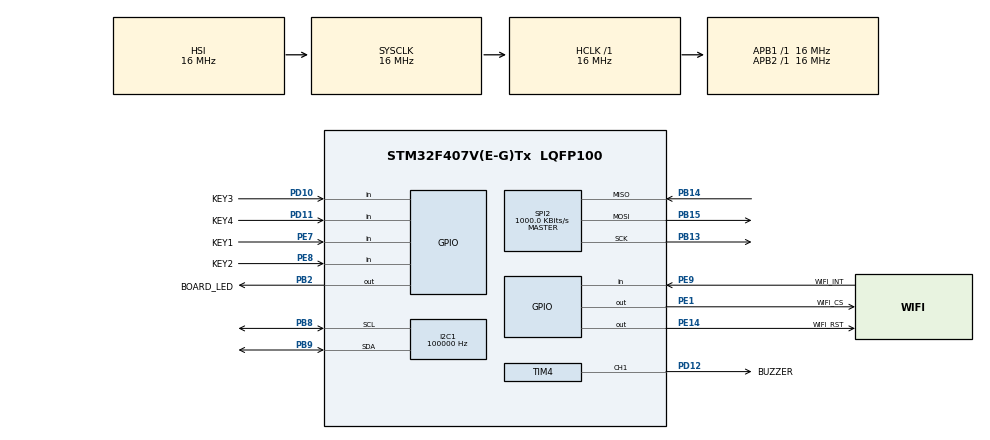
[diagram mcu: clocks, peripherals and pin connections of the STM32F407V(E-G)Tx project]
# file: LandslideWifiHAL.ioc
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Mcu.Family=STM32F4
Mcu.Name=STM32F407V(E-G)Tx
Mcu.Package=LQFP100
NVIC.PriorityGroup=NVIC_PRIORITYGROUP_4
PA13.Mode=Serial_Wire
PA13.Signal=SYS_JTMS-SWDIO
PA14.Mode=Serial_Wire
PA14.Signal=SYS_JTCK-SWCLK
PB8.Mode=I2C
PB8.Signal=I2C1_SCL
PB9.Mode=I2C
PB9.Signal=I2C1_SDA
PB13.Mode=Full_Duplex_Master
PB13.Signal=SPI2_SCK
PB14.Mode=Full_Duplex_Master
PB14.Signal=SPI2_MISO
PB15.Mode=Full_Duplex_Master
PB15.Signal=SPI2_MOSI
PB2.GPIO_Label=BOARD_LED
PB2.Signal=GPIO_Output
PD12.GPIO_Label=BUZZER
PD12.Mode=PWM Generation1 CH1
PD12.Signal=TIM4_CH1
PD10.GPIO_Label=KEY3
PD10.Signal=GPIO_Input
PD11.GPIO_Label=KEY4
PD11.Signal=GPIO_Input
PE1.GPIO_Label=WIFI_CS
PE1.PinState=GPIO_PIN_SET
PE1.Signal=GPIO_Output
PE7.GPIO_Label=KEY1
PE7.Signal=GPIO_Input
PE8.GPIO_Label=KEY2
PE8.Signal=GPIO_Input
PE14.GPIO_Label=WIFI_RST
PE14.PinState=GPIO_PIN_SET
PE14.Signal=GPIO_Output
PE9.GPIO_Label=WIFI_INT
PE9.Signal=GPIO_Input
ProjectManager.HeapSize=0x200
ProjectManager.StackSize=0x400
ProjectManager.TargetToolchain=MDK-ARM V5.32
RCC.AHBFreq_Value=16000000
RCC.APB1Freq_Value=16000000
RCC.APB2Freq_Value=16000000
RCC.CortexFreq_Value=16000000
RCC.HSE_VALUE=25000000
RCC.HSI_VALUE=16000000
RCC.LSE_VALUE=32768
RCC.SYSCLKFreq_VALUE=16000000
RCC.VCOOutputFreq_Value=192000000
SPI2.BaudRatePrescaler=SPI_BAUDRATEPRESCALER_16
SPI2.CalculateBaudRate=1000.0 KBits/s
SPI2.Direction=SPI_DIRECTION_2LINES
SPI2.Mode=SPI_MODE_MASTER
SPI2.VirtualType=VM_MASTER
I2C1.ClockSpeed=100000
I2C1.DutyCycle=I2C_DUTYCYCLE_2
I2C1.Mode=I2C
I2C1.VirtualType=VM_MASTER
TIM4.AutoReloadPreload=TIM_AUTORELOAD_PRELOAD_DISABLE
TIM4.Channel-PWM\ Generation1=TIM_CHANNEL_1
TIM4.Period=1249
TIM4.Prescaler=15
SYS.Debug=Serial Wire
VP_TIM4_VS_ClockSourceINT.Mode=Internal
board=custom

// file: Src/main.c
/* USER CODE BEGIN Header */
/**
  ******************************************************************************
  * @file           : main.c
  * @brief          : Main program body
  ******************************************************************************
  * @attention
  *
  * Copyright (c) 2026 STMicroelectronics.
  * All rights reserved.
  *
  * This software is licensed under terms that can be found in the LICENSE file
  * in the root directory of this software component.
  * If no LICENSE file comes with this software, it is provided AS-IS.
  *
  ******************************************************************************
  */
/* USER CODE END Header */
#include "main.h"

/* USER CODE BEGIN Includes */
#include "app_all.h"

/* USER CODE END Includes */

SPI_HandleTypeDef hspi2;
TIM_HandleTypeDef htim4;
I2C_HandleTypeDef hi2c1;

void SystemClock_Config(void);
static void MX_GPIO_Init(void);
static void MX_SPI2_Init(void);
static void MX_TIM4_Init(void);
static void MX_I2C1_Init(void);

int main(void)
{

  /* MCU Configuration--------------------------------------------------------*/

  /* Reset of all peripherals, Initializes the Flash interface and the Systick. */
  HAL_Init();

  /* Configure the system clock */
  SystemClock_Config();

  /* Initialize all configured peripherals */
  MX_GPIO_Init();
  MX_SPI2_Init();
  MX_TIM4_Init();
  MX_I2C1_Init();
  /* USER CODE BEGIN 2 */
  OLED_UI_Init(&hi2c1);
  wifi_test_app_run(&hspi2);

  /* USER CODE END 2 */

  /* Infinite loop */
  while (1)
  {

  }
}

static void MX_I2C1_Init(void)
{
  hi2c1.Instance = I2C1;
  hi2c1.Init.ClockSpeed = 100000;
  hi2c1.Init.DutyCycle = I2C_DUTYCYCLE_2;
  hi2c1.Init.OwnAddress1 = 0;
  hi2c1.Init.AddressingMode = I2C_ADDRESSINGMODE_7BIT;
  hi2c1.Init.DualAddressMode = I2C_DUALADDRESS_DISABLE;
  hi2c1.Init.OwnAddress2 = 0;
  hi2c1.Init.GeneralCallMode = I2C_GENERALCALL_DISABLE;
  hi2c1.Init.NoStretchMode = I2C_NOSTRETCH_DISABLE;
  if (HAL_I2C_Init(&hi2c1) != HAL_OK) Error_Handler();
}

void SystemClock_Config(void)
{
  RCC_OscInitTypeDef RCC_OscInitStruct = {0};
  RCC_ClkInitTypeDef RCC_ClkInitStruct = {0};

  /** Configure the main internal regulator output voltage
  */
  __HAL_RCC_PWR_CLK_ENABLE();
  __HAL_PWR_VOLTAGESCALING_CONFIG(PWR_REGULATOR_VOLTAGE_SCALE1);

  /** Initializes the RCC Oscillators according to the specified parameters
  * in the RCC_OscInitTypeDef structure.
  */
  RCC_OscInitStruct.OscillatorType = RCC_OSCILLATORTYPE_HSI;
  RCC_OscInitStruct.HSIState = RCC_HSI_ON;
  RCC_OscInitStruct.HSICalibrationValue = RCC_HSICALIBRATION_DEFAULT;
  RCC_OscInitStruct.PLL.PLLState = RCC_PLL_NONE;
  if (HAL_RCC_OscConfig(&RCC_OscInitStruct) != HAL_OK)
  {
    Error_Handler();
  }

  /** Initializes the CPU, AHB and APB buses clocks
  */
  RCC_ClkInitStruct.ClockType = RCC_CLOCKTYPE_HCLK|RCC_CLOCKTYPE_SYSCLK
                              |RCC_CLOCKTYPE_PCLK1|RCC_CLOCKTYPE_PCLK2;
  RCC_ClkInitStruct.SYSCLKSource = RCC_SYSCLKSOURCE_HSI;
  RCC_ClkInitStruct.AHBCLKDivider = RCC_SYSCLK_DIV1;
  RCC_ClkInitStruct.APB1CLKDivider = RCC_HCLK_DIV1;
  RCC_ClkInitStruct.APB2CLKDivider = RCC_HCLK_DIV1;

  if (HAL_RCC_ClockConfig(&RCC_ClkInitStruct, FLASH_LATENCY_0) != HAL_OK)
  {
    Error_Handler();
  }
}

static void MX_SPI2_Init(void)
{

  /* SPI2 parameter configuration*/
  hspi2.Instance = SPI2;
  hspi2.Init.Mode = SPI_MODE_MASTER;
  hspi2.Init.Direction = SPI_DIRECTION_2LINES;
  hspi2.Init.DataSize = SPI_DATASIZE_8BIT;
  hspi2.Init.CLKPolarity = SPI_POLARITY_LOW;
  hspi2.Init.CLKPhase = SPI_PHASE_1EDGE;
  hspi2.Init.NSS = SPI_NSS_SOFT;
  hspi2.Init.BaudRatePrescaler = SPI_BAUDRATEPRESCALER_16;
  hspi2.Init.FirstBit = SPI_FIRSTBIT_MSB;
  hspi2.Init.TIMode = SPI_TIMODE_DISABLE;
  hspi2.Init.CRCCalculation = SPI_CRCCALCULATION_DISABLE;
  hspi2.Init.CRCPolynomial = 10;
  if (HAL_SPI_Init(&hspi2) != HAL_OK)
  {
    Error_Handler();
  }

}

static void MX_TIM4_Init(void)
{
  GPIO_InitTypeDef GPIO_InitStruct = {0};
  TIM_OC_InitTypeDef sConfigOC = {0};

  __HAL_RCC_TIM4_CLK_ENABLE();
  __HAL_RCC_GPIOD_CLK_ENABLE();

  htim4.Instance = TIM4;
  htim4.Init.Prescaler = 15;
  htim4.Init.CounterMode = TIM_COUNTERMODE_UP;
  htim4.Init.Period = 1249;
  htim4.Init.ClockDivision = TIM_CLOCKDIVISION_DIV1;
  htim4.Init.AutoReloadPreload = TIM_AUTORELOAD_PRELOAD_DISABLE;
  if (HAL_TIM_PWM_Init(&htim4) != HAL_OK) Error_Handler();

  sConfigOC.OCMode = TIM_OCMODE_PWM1;
  sConfigOC.Pulse = 0;
  sConfigOC.OCPolarity = TIM_OCPOLARITY_HIGH;
  sConfigOC.OCFastMode = TIM_OCFAST_DISABLE;
  if (HAL_TIM_PWM_ConfigChannel(&htim4, &sConfigOC, TIM_CHANNEL_1) != HAL_OK)
    Error_Handler();

  GPIO_InitStruct.Pin = BUZZER_Pin;
  GPIO_InitStruct.Mode = GPIO_MODE_AF_PP;
  GPIO_InitStruct.Pull = GPIO_NOPULL;
  GPIO_InitStruct.Speed = GPIO_SPEED_FREQ_LOW;
  GPIO_InitStruct.Alternate = GPIO_AF2_TIM4;
  HAL_GPIO_Init(BUZZER_GPIO_Port, &GPIO_InitStruct);

  if (HAL_TIM_PWM_Start(&htim4, TIM_CHANNEL_1) != HAL_OK) Error_Handler();
}

static void MX_GPIO_Init(void)
{
  GPIO_InitTypeDef GPIO_InitStruct = {0};

  /* GPIO Ports Clock Enable */
  __HAL_RCC_GPIOB_CLK_ENABLE();
  __HAL_RCC_GPIOE_CLK_ENABLE();
  __HAL_RCC_GPIOD_CLK_ENABLE();
  __HAL_RCC_GPIOA_CLK_ENABLE();

  /*Configure GPIO pin Output Level */
  HAL_GPIO_WritePin(BOARD_LED_GPIO_Port, BOARD_LED_Pin, GPIO_PIN_RESET);

  /*Configure GPIO pin Output Level */
  HAL_GPIO_WritePin(GPIOE, WIFI_RST_Pin|WIFI_CS_Pin, GPIO_PIN_SET);

  /*Configure GPIO pin : BOARD_LED_Pin */
  GPIO_InitStruct.Pin = BOARD_LED_Pin;
  GPIO_InitStruct.Mode = GPIO_MODE_OUTPUT_PP;
  GPIO_InitStruct.Pull = GPIO_NOPULL;
  GPIO_InitStruct.Speed = GPIO_SPEED_FREQ_LOW;
  HAL_GPIO_Init(BOARD_LED_GPIO_Port, &GPIO_InitStruct);

  /*Configure GPIO pin : WIFI_INT_Pin */
  GPIO_InitStruct.Pin = WIFI_INT_Pin;
  GPIO_InitStruct.Mode = GPIO_MODE_INPUT;
  GPIO_InitStruct.Pull = GPIO_NOPULL;
  HAL_GPIO_Init(WIFI_INT_GPIO_Port, &GPIO_InitStruct);

  /*Configure GPIO pins : WIFI_RST_Pin WIFI_CS_Pin */
  GPIO_InitStruct.Pin = WIFI_RST_Pin|WIFI_CS_Pin;
  GPIO_InitStruct.Mode = GPIO_MODE_OUTPUT_PP;
  GPIO_InitStruct.Pull = GPIO_NOPULL;
  GPIO_InitStruct.Speed = GPIO_SPEED_FREQ_LOW;
  HAL_GPIO_Init(GPIOE, &GPIO_InitStruct);

  /* USER CODE BEGIN MX_GPIO_Init_2 */

  GPIO_InitStruct.Pin = KEY1_Pin|KEY2_Pin;
  GPIO_InitStruct.Mode = GPIO_MODE_INPUT;
  GPIO_InitStruct.Pull = GPIO_NOPULL;
  HAL_GPIO_Init(GPIOE, &GPIO_InitStruct);

  GPIO_InitStruct.Pin = KEY3_Pin|KEY4_Pin;
  GPIO_InitStruct.Mode = GPIO_MODE_INPUT;
  GPIO_InitStruct.Pull = GPIO_NOPULL;
  HAL_GPIO_Init(GPIOD, &GPIO_InitStruct);

  /* USER CODE END MX_GPIO_Init_2 */
}

void Error_Handler(void)
{
  __disable_irq();
  while (1)
  {
  }
}
